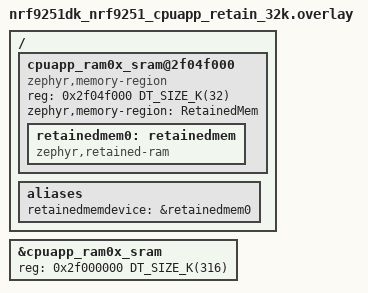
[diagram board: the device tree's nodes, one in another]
#include "nrf9251dk_nrf9251_cpuapp.overlay"

/ {
	cpuapp_ram0x_sram@2f04f000 {
		compatible = "zephyr,memory-region", "mmio-sram";
		reg = <0x2f04f000 DT_SIZE_K(32)>;
		zephyr,memory-region = "RetainedMem";
		status = "okay";

		retainedmem0: retainedmem {
			compatible = "zephyr,retained-ram";
			status = "okay";
		};
	};

	aliases {
		retainedmemdevice = &retainedmem0;
	};
};

&cpuapp_ram0x_sram {
	/* Shrink SRAM size to avoid overlap with retained memory region:
	 * 348 - 32 = 316 (0x4f000)
	 */
	reg = <0x2f000000 DT_SIZE_K(316)>;
	ranges = <0x0 0x2f000000 DT_SIZE_K(316)>;
};
